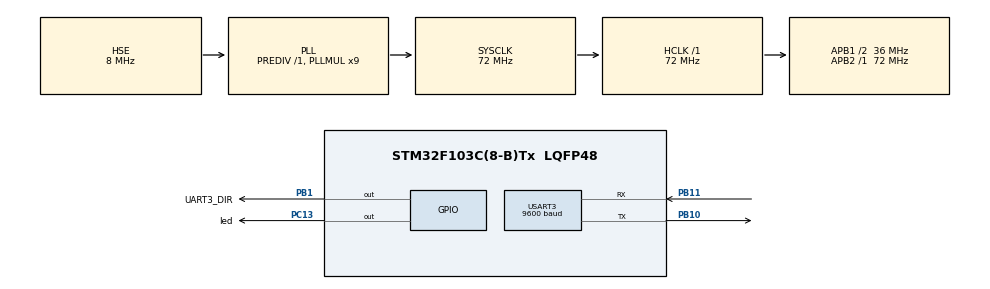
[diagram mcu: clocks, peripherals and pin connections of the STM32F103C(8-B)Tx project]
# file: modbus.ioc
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Dma.Request0=USART3_RX
Dma.USART3_RX.0.Direction=DMA_PERIPH_TO_MEMORY
Dma.USART3_RX.0.Instance=DMA1_Channel3
Dma.USART3_RX.0.MemDataAlignment=DMA_MDATAALIGN_BYTE
Dma.USART3_RX.0.MemInc=DMA_MINC_ENABLE
Dma.USART3_RX.0.Mode=DMA_CIRCULAR
Dma.USART3_RX.0.PeriphDataAlignment=DMA_PDATAALIGN_BYTE
Dma.USART3_RX.0.PeriphInc=DMA_PINC_DISABLE
Dma.USART3_RX.0.Priority=DMA_PRIORITY_MEDIUM
Mcu.Family=STM32F1
Mcu.Name=STM32F103C(8-B)Tx
Mcu.Package=LQFP48
NVIC.DMA1_Channel3_IRQn=true\:0\:0\:false\:false\:true\:false\:true\:true
NVIC.PriorityGroup=NVIC_PRIORITYGROUP_4
PA13.Mode=Serial_Wire
PA13.Signal=SYS_JTMS-SWDIO
PA14.Mode=Serial_Wire
PA14.Signal=SYS_JTCK-SWCLK
PB1.GPIO_Label=UART3_DIR
PB1.Signal=GPIO_Output
PB10.Mode=Asynchronous
PB10.Signal=USART3_TX
PB11.Mode=Asynchronous
PB11.Signal=USART3_RX
PC13-TAMPER-RTC.GPIO_Label=led
PC13-TAMPER-RTC.Signal=GPIO_Output
PD0-OSC_IN.Mode=HSE-External-Oscillator
PD0-OSC_IN.Signal=RCC_OSC_IN
PD1-OSC_OUT.Mode=HSE-External-Oscillator
PD1-OSC_OUT.Signal=RCC_OSC_OUT
ProjectManager.HeapSize=0x200
ProjectManager.StackSize=0x400
ProjectManager.TargetToolchain=STM32CubeIDE
RCC.AHBFreq_Value=72000000
RCC.APB1CLKDivider=RCC_HCLK_DIV2
RCC.APB1Freq_Value=36000000
RCC.APB1TimFreq_Value=72000000
RCC.APB2Freq_Value=72000000
RCC.APB2TimFreq_Value=72000000
RCC.HCLKFreq_Value=72000000
RCC.PLLMUL=RCC_PLL_MUL9
RCC.PLLSourceVirtual=RCC_PLLSOURCE_HSE
RCC.SYSCLKFreq_VALUE=72000000
RCC.SYSCLKSource=RCC_SYSCLKSOURCE_PLLCLK
RCC.USBFreq_Value=72000000
USART3.BaudRate=9600
USART3.VirtualMode=VM_ASYNC
USART3.WordLength=WORDLENGTH_8B
board=custom

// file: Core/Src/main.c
/* USER CODE BEGIN Header */
/**
  ******************************************************************************
  * @file           : main.c
  * @brief          : Main program body
  ******************************************************************************
  * @attention
  *
  * Copyright (c) 2022 STMicroelectronics.
  * All rights reserved.
  *
  * This software is licensed under terms that can be found in the LICENSE file
  * in the root directory of this software component.
  * If no LICENSE file comes with this software, it is provided AS-IS.
  *
  ******************************************************************************
  */
/* USER CODE END Header */
#include "main.h"

/* USER CODE BEGIN Includes */
#include "modbus.h"
/* USER CODE END Includes */

UART_HandleTypeDef huart3;
DMA_HandleTypeDef hdma_usart3_rx;

/* USER CODE BEGIN PV */
uint8_t modbus_data[8];
/* USER CODE END PV */

void SystemClock_Config(void);
static void MX_GPIO_Init(void);
static void MX_DMA_Init(void);
static void MX_USART3_UART_Init(void);

/* USER CODE BEGIN 0 */
uint8_t pData[8];
/* USER CODE END 0 */

int main(void)
{

  /* MCU Configuration--------------------------------------------------------*/

  /* Reset of all peripherals, Initializes the Flash interface and the Systick. */
  HAL_Init();

  /* Configure the system clock */
  SystemClock_Config();

  /* Initialize all configured peripherals */
  MX_GPIO_Init();
  MX_DMA_Init();
  MX_USART3_UART_Init();
  /* USER CODE BEGIN 2 */
//  HAL_GPIO_WritePin(UART3_DIR_GPIO_Port, UART3_DIR_Pin, 0);
//  HAL_Delay(1000);
//  HAL_UART_Receive_DMA(&huart3, pData, 8);
//  HAL_Delay(1000);
  modbus_slave_init();
  modbus_data[0] = 45;
  modbus_data[1] = 55;
  /* USER CODE END 2 */

  /* Infinite loop */
  /* USER CODE BEGIN WHILE */
  while (1)
  {

	  modbus_slave_loop(0x3, modbus_data);
	  HAL_Delay(100);
    /* USER CODE END WHILE */

  }
}

void SystemClock_Config(void)
{
  RCC_OscInitTypeDef RCC_OscInitStruct = {0};
  RCC_ClkInitTypeDef RCC_ClkInitStruct = {0};

  /** Initializes the RCC Oscillators according to the specified parameters
  * in the RCC_OscInitTypeDef structure.
  */
  RCC_OscInitStruct.OscillatorType = RCC_OSCILLATORTYPE_HSE;
  RCC_OscInitStruct.HSEState = RCC_HSE_ON;
  RCC_OscInitStruct.HSEPredivValue = RCC_HSE_PREDIV_DIV1;
  RCC_OscInitStruct.HSIState = RCC_HSI_ON;
  RCC_OscInitStruct.PLL.PLLState = RCC_PLL_ON;
  RCC_OscInitStruct.PLL.PLLSource = RCC_PLLSOURCE_HSE;
  RCC_OscInitStruct.PLL.PLLMUL = RCC_PLL_MUL9;
  if (HAL_RCC_OscConfig(&RCC_OscInitStruct) != HAL_OK)
  {
    Error_Handler();
  }

  /** Initializes the CPU, AHB and APB buses clocks
  */
  RCC_ClkInitStruct.ClockType = RCC_CLOCKTYPE_HCLK|RCC_CLOCKTYPE_SYSCLK
                              |RCC_CLOCKTYPE_PCLK1|RCC_CLOCKTYPE_PCLK2;
  RCC_ClkInitStruct.SYSCLKSource = RCC_SYSCLKSOURCE_PLLCLK;
  RCC_ClkInitStruct.AHBCLKDivider = RCC_SYSCLK_DIV1;
  RCC_ClkInitStruct.APB1CLKDivider = RCC_HCLK_DIV2;
  RCC_ClkInitStruct.APB2CLKDivider = RCC_HCLK_DIV1;

  if (HAL_RCC_ClockConfig(&RCC_ClkInitStruct, FLASH_LATENCY_2) != HAL_OK)
  {
    Error_Handler();
  }
}

static void MX_USART3_UART_Init(void)
{

  huart3.Instance = USART3;
  huart3.Init.BaudRate = 9600;
  huart3.Init.WordLength = UART_WORDLENGTH_8B;
  huart3.Init.StopBits = UART_STOPBITS_1;
  huart3.Init.Parity = UART_PARITY_NONE;
  huart3.Init.Mode = UART_MODE_TX_RX;
  huart3.Init.HwFlowCtl = UART_HWCONTROL_NONE;
  huart3.Init.OverSampling = UART_OVERSAMPLING_16;
  if (HAL_UART_Init(&huart3) != HAL_OK)
  {
    Error_Handler();
  }

}

static void MX_DMA_Init(void)
{

  /* DMA controller clock enable */
  __HAL_RCC_DMA1_CLK_ENABLE();

  /* DMA interrupt init */
  /* DMA1_Channel3_IRQn interrupt configuration */
  HAL_NVIC_SetPriority(DMA1_Channel3_IRQn, 0, 0);
  HAL_NVIC_EnableIRQ(DMA1_Channel3_IRQn);

}

static void MX_GPIO_Init(void)
{
  GPIO_InitTypeDef GPIO_InitStruct = {0};

  /* GPIO Ports Clock Enable */
  __HAL_RCC_GPIOC_CLK_ENABLE();
  __HAL_RCC_GPIOD_CLK_ENABLE();
  __HAL_RCC_GPIOB_CLK_ENABLE();
  __HAL_RCC_GPIOA_CLK_ENABLE();

  /*Configure GPIO pin Output Level */
  HAL_GPIO_WritePin(led_GPIO_Port, led_Pin, GPIO_PIN_RESET);

  /*Configure GPIO pin Output Level */
  HAL_GPIO_WritePin(UART3_DIR_GPIO_Port, UART3_DIR_Pin, GPIO_PIN_RESET);

  /*Configure GPIO pin : led_Pin */
  GPIO_InitStruct.Pin = led_Pin;
  GPIO_InitStruct.Mode = GPIO_MODE_OUTPUT_PP;
  GPIO_InitStruct.Pull = GPIO_NOPULL;
  GPIO_InitStruct.Speed = GPIO_SPEED_FREQ_LOW;
  HAL_GPIO_Init(led_GPIO_Port, &GPIO_InitStruct);

  /*Configure GPIO pin : UART3_DIR_Pin */
  GPIO_InitStruct.Pin = UART3_DIR_Pin;
  GPIO_InitStruct.Mode = GPIO_MODE_OUTPUT_PP;
  GPIO_InitStruct.Pull = GPIO_NOPULL;
  GPIO_InitStruct.Speed = GPIO_SPEED_FREQ_LOW;
  HAL_GPIO_Init(UART3_DIR_GPIO_Port, &GPIO_InitStruct);

}

void Error_Handler(void)
{
  __disable_irq();
  while (1)
  {
  }
}
